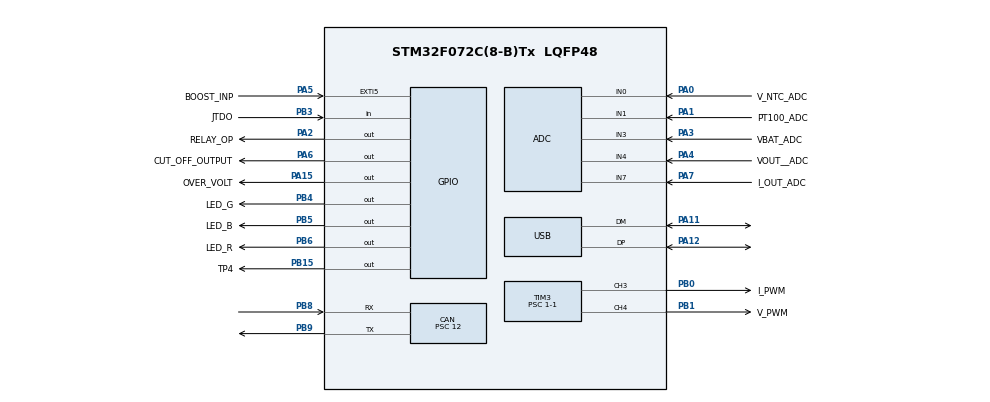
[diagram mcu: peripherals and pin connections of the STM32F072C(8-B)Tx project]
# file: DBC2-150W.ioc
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ADC.ContinuousConvMode=ENABLE
ADC.DMAContinuousRequests=ENABLE
ADC.EOCSelection=ADC_EOC_SEQ_CONV
ADC.Overrun=ADC_OVR_DATA_OVERWRITTEN
ADC.SamplingTime=ADC_SAMPLETIME_71CYCLES_5
CAN.BS1=CAN_BS1_13TQ
CAN.BS2=CAN_BS2_2TQ
CAN.CalculateBaudRate=250000
CAN.CalculateTimeBit=4000
CAN.CalculateTimeQuantum=250.0
CAN.Mode=CAN_MODE_LOOPBACK
CAN.NART=ENABLE
CAN.Prescaler=12
CAN.SJW=CAN_SJW_1TQ
CAN.TTCM=DISABLE
Dma.ADC.0.Direction=DMA_PERIPH_TO_MEMORY
Dma.ADC.0.Instance=DMA1_Channel1
Dma.ADC.0.MemDataAlignment=DMA_MDATAALIGN_HALFWORD
Dma.ADC.0.MemInc=DMA_MINC_ENABLE
Dma.ADC.0.Mode=DMA_CIRCULAR
Dma.ADC.0.PeriphDataAlignment=DMA_PDATAALIGN_HALFWORD
Dma.ADC.0.PeriphInc=DMA_PINC_DISABLE
Dma.ADC.0.Priority=DMA_PRIORITY_HIGH
Dma.Request0=ADC
Mcu.Family=STM32F0
Mcu.Name=STM32F072C(8-B)Tx
Mcu.Package=LQFP48
NVIC.CEC_CAN_IRQn=true\:0\:0\:false\:false\:true\:true\:true\:true
NVIC.EXTI4_15_IRQn=true\:2\:0\:true\:false\:true\:true\:true\:true
NVIC.TIM14_IRQn=true\:1\:0\:true\:false\:true\:true\:true\:true
NVIC.TIM15_IRQn=true\:3\:0\:false\:false\:true\:false\:true\:true
NVIC.TimeBase=TIM15_IRQn
NVIC.TimeBaseIP=TIM15
NVIC.USB_IRQn=true\:0\:0\:true\:false\:true\:false\:true\:true
PA0.GPIO_Label=V_NTC_ADC
PA0.Mode=IN0
PA0.Signal=ADC_IN0
PA1.GPIO_Label=PT100_ADC
PA1.Mode=IN1
PA1.Signal=ADC_IN1
PA11.Mode=Device
PA11.Signal=USB_DM
PA12.Mode=Device
PA12.Signal=USB_DP
PA13.Mode=Serial_Wire
PA13.Signal=SYS_SWDIO
PA14.Mode=Serial_Wire
PA14.Signal=SYS_SWCLK
PA15.GPIO_Label=OVER_VOLT
PA15.Signal=GPIO_Output
PA2.GPIO_Label=RELAY_OP
PA2.Signal=GPIO_Output
PA3.GPIO_Label=VBAT_ADC
PA3.Mode=IN3
PA3.Signal=ADC_IN3
PA4.GPIO_Label=VOUT__ADC
PA4.Mode=IN4
PA4.Signal=ADC_IN4
PA5.GPIO_Label=BOOST_INP
PA5.GPIO_ModeDefaultEXTI=GPIO_MODE_IT_RISING_FALLING
PA5.Signal=GPXTI5
PA6.GPIO_Label=CUT_OFF_OUTPUT
PA6.Signal=GPIO_Output
PA7.GPIO_Label=I_OUT_ADC
PA7.Mode=IN7
PA7.Signal=ADC_IN7
PB0.GPIO_Label=I_PWM
PB0.Signal=S_TIM3_CH3
PB1.GPIO_Label=V_PWM
PB1.Signal=S_TIM3_CH4
PB15.GPIO_Label=TP4
PB15.Signal=GPIO_Output
PB3.GPIO_Label=JTDO
PB3.Signal=GPIO_Input
PB4.GPIO_Label=LED_G
PB4.Signal=GPIO_Output
PB5.GPIO_Label=LED_B
PB5.Signal=GPIO_Output
PB6.GPIO_Label=LED_R
PB6.Signal=GPIO_Output
PB8.Mode=CAN_Activate
PB8.Signal=CAN_RX
PB9.Mode=CAN_Activate
PB9.Signal=CAN_TX
ProjectManager.HeapSize=0x200
ProjectManager.StackSize=0x400
ProjectManager.TargetToolchain=STM32CubeIDE
RCC.AHBFreq_Value=48000000
RCC.APB1Freq_Value=48000000
RCC.APB1TimFreq_Value=48000000
RCC.HCLKFreq_Value=48000000
RCC.SYSCLKFreq_VALUE=48000000
RCC.SYSCLKSource=RCC_SYSCLKSOURCE_HSI48
SH.S_TIM3_CH3.0=TIM3_CH3,PWM Generation3 CH3
SH.S_TIM3_CH4.0=TIM3_CH4,PWM Generation4 CH4
TIM14.AutoReloadPreload=TIM_AUTORELOAD_PRELOAD_DISABLE
TIM14.Period=12000-1
TIM14.Prescaler=4-1
TIM3.Channel-PWM\ Generation3\ CH3=TIM_CHANNEL_3
TIM3.Channel-PWM\ Generation4\ CH4=TIM_CHANNEL_4
TIM3.Period=1000-1
TIM3.Prescaler=1-1
USB_DEVICE.CLASS_NAME_FS=CDC
USB_DEVICE.MANUFACTURER_STRING=EN-KO Control Systems
USB_DEVICE.VirtualMode=Cdc
USB_DEVICE.VirtualModeFS=Cdc_FS
VP_ADC_TempSens_Input.Mode=IN-TempSens
VP_IWDG_VS_IWDG.Mode=IWDG_Activate
VP_SYS_VS_tim15.Mode=TIM15
VP_TIM14_VS_ClockSourceINT.Mode=Enable_Timer
VP_USB_DEVICE_VS_USB_DEVICE_CDC_FS.Mode=CDC_FS
board=custom

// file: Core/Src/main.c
/* USER CODE BEGIN Header */
/**
  ******************************************************************************
  * @file           : main.c
  * @brief          : Main program body
  ******************************************************************************
  * @attention
  * DBC2 Battery Charger Project Developed by ENKO Control Systems
  ******************************************************************************
  */
/* USER CODE END Header */
#include "main.h"
#include "adc.h"
#include "can.h"
#include "dma.h"
#include "iwdg.h"
#include "tim.h"
#include "usb_device.h"
#include "gpio.h"

/* USER CODE BEGIN Includes */
#include "Interfaces.h"
/* USER CODE END Includes */

void SystemClock_Config(void);

int main(void)
{
  /* USER CODE BEGIN 1 */
  _initVectorTable();
  /* USER CODE END 1 */

  /* MCU Configuration--------------------------------------------------------*/

  /* Reset of all peripherals, Initializes the Flash interface and the Systick. */
  HAL_Init();

  /* Configure the system clock */
  SystemClock_Config();

  /* USER CODE BEGIN SysInit */
  #ifndef DEBUG_MODE_OPTIONS
  _lockOB();
  #endif
  /* USER CODE END SysInit */

  /* Initialize all configured peripherals */
  MX_GPIO_Init();
  MX_DMA_Init();
  MX_ADC_Init();
  MX_USB_DEVICE_Init();
  MX_TIM14_Init();
  MX_TIM3_Init();
  MX_IWDG_Init();
  MX_CAN_Init();
  /* USER CODE BEGIN 2 */
  _corePostInit();
  /* USER CODE END 2 */

  /* Infinite loop */
	while (1)
	{

    /* USER CODE BEGIN 3 */
	  _coreLoop();
	}
  /* USER CODE END 3 */
}

void SystemClock_Config(void)
{
  LL_FLASH_SetLatency(LL_FLASH_LATENCY_1);
  while(LL_FLASH_GetLatency() != LL_FLASH_LATENCY_1)
  {
  }
  LL_RCC_HSI14_Enable();

   /* Wait till HSI14 is ready */
  while(LL_RCC_HSI14_IsReady() != 1)
  {

  }
  LL_RCC_HSI14_SetCalibTrimming(16);
  LL_RCC_HSI48_Enable();

   /* Wait till HSI48 is ready */
  while(LL_RCC_HSI48_IsReady() != 1)
  {

  }
  LL_RCC_LSI_Enable();

   /* Wait till LSI is ready */
  while(LL_RCC_LSI_IsReady() != 1)
  {

  }
  LL_RCC_SetAHBPrescaler(LL_RCC_SYSCLK_DIV_1);
  LL_RCC_SetAPB1Prescaler(LL_RCC_APB1_DIV_1);
  LL_RCC_SetSysClkSource(LL_RCC_SYS_CLKSOURCE_HSI48);

   /* Wait till System clock is ready */
  while(LL_RCC_GetSysClkSource() != LL_RCC_SYS_CLKSOURCE_STATUS_HSI48)
  {

  }
  LL_SetSystemCoreClock(48000000);

   /* Update the time base */
  if (HAL_InitTick (TICK_INT_PRIORITY) != HAL_OK)
  {
    Error_Handler();
  }
  LL_RCC_HSI14_EnableADCControl();
  LL_RCC_SetUSBClockSource(LL_RCC_USB_CLKSOURCE_HSI48);
}

void HAL_TIM_PeriodElapsedCallback(TIM_HandleTypeDef *htim)
{
  if (htim->Instance == TIM15) {
    HAL_IncTick();
  }
  /* USER CODE BEGIN Callback 1 */
  if (htim->Instance == TIMER_1MS.Instance){
    Callback1ms();
  }
  /* USER CODE END Callback 1 */
}

void Error_Handler(void)
{
  __disable_irq();
  while (1)
  {
  }
}
